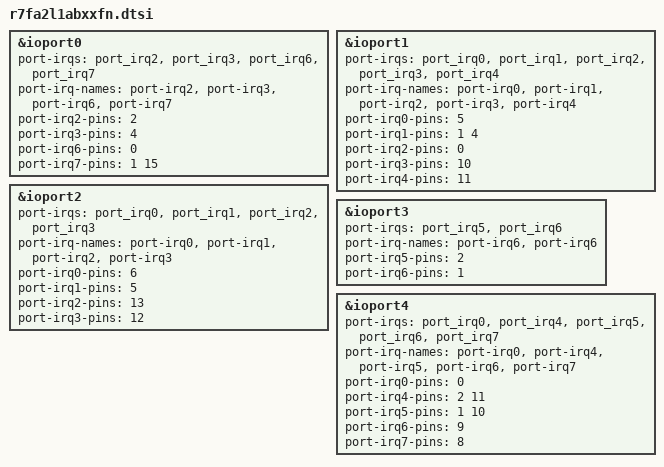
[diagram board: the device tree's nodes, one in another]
/**
 * Copyright (c) 2025 Renesas Electronics Corporation
 *
 * Renesas R7FA2AL1ABxxFN MCU device tree for 256KB code flash 80 pins
 *
 * SPDX-License-Identifier: Apache-2.0
 *
 */

#include <arm/renesas/ra/ra2/ra2l1.dtsi>
#include <arm/renesas/ra/ra2/r7fa2l1xb.dtsi>

&ioport0 {
	port-irqs = <&port_irq2 &port_irq3 &port_irq6
		     &port_irq7>;
	port-irq-names = "port-irq2",
			 "port-irq3",
			 "port-irq6",
			 "port-irq7";
	port-irq2-pins = <2>;
	port-irq3-pins = <4>;
	port-irq6-pins = <0>;
	port-irq7-pins = <1 15>;
};

&ioport1 {
	port-irqs = <&port_irq0 &port_irq1 &port_irq2
		     &port_irq3 &port_irq4>;
	port-irq-names = "port-irq0",
			 "port-irq1",
			 "port-irq2",
			 "port-irq3",
			 "port-irq4";
	port-irq0-pins = <5>;
	port-irq1-pins = <1 4>;
	port-irq2-pins = <0>;
	port-irq3-pins = <10>;
	port-irq4-pins = <11>;
};

&ioport2 {
	port-irqs = <&port_irq0 &port_irq1 &port_irq2
		     &port_irq3>;
	port-irq-names = "port-irq0",
			 "port-irq1",
			 "port-irq2",
			 "port-irq3";
	port-irq0-pins = <6>;
	port-irq1-pins = <5>;
	port-irq2-pins = <13>;
	port-irq3-pins = <12>;
};

&ioport3 {
	port-irqs = <&port_irq5 &port_irq6>;
	port-irq-names = "port-irq6",
			 "port-irq6";
	port-irq5-pins = <2>;
	port-irq6-pins = <1>;
};

&ioport4 {
	port-irqs = <&port_irq0 &port_irq4 &port_irq5
		     &port_irq6 &port_irq7>;
	port-irq-names = "port-irq0",
			 "port-irq4",
			 "port-irq5",
			 "port-irq6",
			 "port-irq7";
	port-irq0-pins = <0>;
	port-irq4-pins = <2 11>;
	port-irq5-pins = <1 10>;
	port-irq6-pins = <9>;
	port-irq7-pins = <8>;
};
